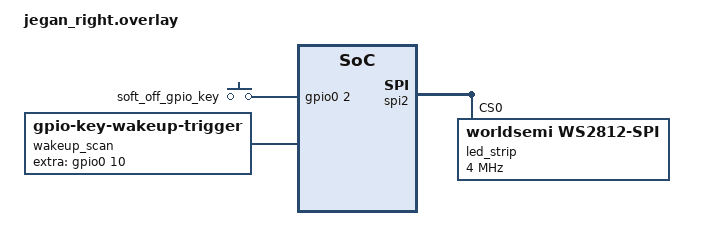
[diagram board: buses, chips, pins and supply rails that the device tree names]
// This file was generated from a template. Edit it to match your keyboard.
// See https://zmk.dev/docs/development/hardware-integration/new-shield for more
// instructions.

#include "jegan.dtsi"

&default_transform {
    // Set this to the number of columns on the left side.
    col-offset = <7>;
};

&kscan {
    // Replace these comments with the GPIO pins in the matrix for the right side.
    // See https://zmk.dev/docs/development/hardware-integration/new-shield#shield-overlays
    col-gpios
        = <&gpio0 10 GPIO_ACTIVE_HIGH> // D16
        , <&gpio0  9 GPIO_ACTIVE_HIGH> // D10
        , <&gpio1  6 GPIO_ACTIVE_HIGH> // D9
        , <&gpio1  4 GPIO_ACTIVE_HIGH> // D8
        , <&gpio0 11 GPIO_ACTIVE_HIGH> // D7
        , <&gpio1  0 GPIO_ACTIVE_HIGH> // D6
        , <&gpio0 24 GPIO_ACTIVE_HIGH> // D5
        , <&gpio0  6 GPIO_ACTIVE_HIGH> // D1
        ;

    row-gpios
        = <&gpio0 31 (GPIO_ACTIVE_HIGH | GPIO_PULL_DOWN)>
        , <&gpio0 29 (GPIO_ACTIVE_HIGH | GPIO_PULL_DOWN)>
        , <&gpio0  2 (GPIO_ACTIVE_HIGH | GPIO_PULL_DOWN)>
        , <&gpio1 15 (GPIO_ACTIVE_HIGH | GPIO_PULL_DOWN)>
        , <&gpio1 13 (GPIO_ACTIVE_HIGH | GPIO_PULL_DOWN)>
        , <&gpio1 11 (GPIO_ACTIVE_HIGH | GPIO_PULL_DOWN)>
        ;
};

&spi2 {
    compatible = "nordic,nrf-spim";
	status = "okay";
    pinctrl-0 = <&spi2_default>;
    pinctrl-1 = <&spi2_sleep>;
    pinctrl-names = "default", "sleep";

	led_strip: ws2812@0 {
		compatible = "worldsemi,ws2812-spi";

		/* SPI */
		reg = <0>; /* ignored, but necessary for SPI bindings */
		spi-max-frequency = <DT_FREQ_M(4)>;

		/* WS2812 */
		chain-length = <47>; /* arbitrary; change at will */
		spi-one-frame = <0x70>;
		spi-zero-frame = <0x40>;

        color-mapping = <
            LED_COLOR_ID_GREEN
            LED_COLOR_ID_RED
            LED_COLOR_ID_BLUE
            >;
	};
};

/ {
    keys {
        compatible = "gpio-keys";
        soft_off_gpio_key: soft_off_gpio_key {
            gpios = <&gpio0 2 (GPIO_ACTIVE_HIGH | GPIO_PULL_DOWN)>;
        };
    };

    wakeup_scan: wakeup_scan {
        compatible = "zmk,gpio-key-wakeup-trigger";
        trigger = <&soft_off_gpio_key>;
        wakeup-source;
        extra-gpios = <&gpio0 10 GPIO_ACTIVE_HIGH>;
    };
};
